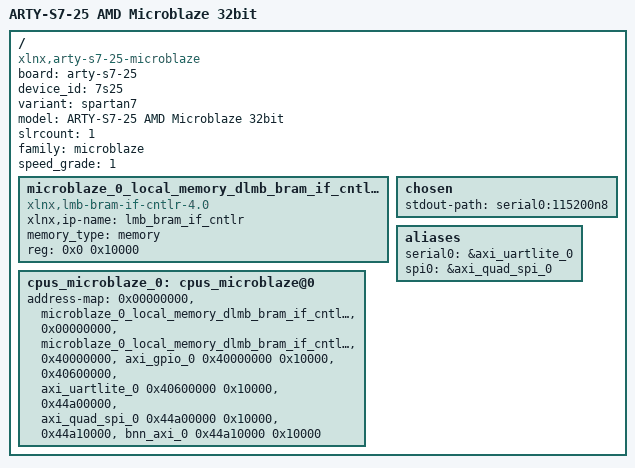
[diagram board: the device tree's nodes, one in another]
/dts-v1/;
#include "pl.dtsi"
/ {
	board = "arty-s7-25";
	compatible = "xlnx,arty-s7-25-microblaze";
	device_id = "7s25";
	#address-cells = <1>;
	variant = "spartan7";
	model = "ARTY-S7-25 AMD Microblaze 32bit";
	#size-cells = <1>;
	slrcount = <1>;
	family = "microblaze";
	speed_grade = "1";
	microblaze_0_local_memory_dlmb_bram_if_cntlr_memory: memory@0 {
		ranges = <0 0x0 0x10000>;
		compatible = "xlnx,lmb-bram-if-cntlr-4.0" , "mmio-sram";
		#address-cells = <1>;
		xlnx,ip-name = "lmb_bram_if_cntlr";
		device_type = "memory";
		#size-cells = <1>;
		memory_type = "memory";
		reg = <0x0 0x10000>;
	};
	chosen {
		stdout-path = "serial0:115200n8";
	};
	aliases {
		serial0 = &axi_uartlite_0;
		spi0 = &axi_quad_spi_0;
	};
	cpus_microblaze_0: cpus_microblaze@0 {
		address-map = <0x00000000 &microblaze_0_local_memory_dlmb_bram_if_cntlr_memory 0x00000000 0x10000>, 
			      <0x00000000 &microblaze_0_local_memory_dlmb_bram_if_cntlr 0x00000000 0x10000>, 
			      <0x40000000 &axi_gpio_0 0x40000000 0x10000>, 
			      <0x40600000 &axi_uartlite_0 0x40600000 0x10000>, 
			      <0x44a00000 &axi_quad_spi_0 0x44a00000 0x10000>, 
			      <0x44a10000 &bnn_axi_0 0x44a10000 0x10000>;
		#ranges-address-cells = <0x1>;
		#ranges-size-cells = <0x1>;
	};
};
